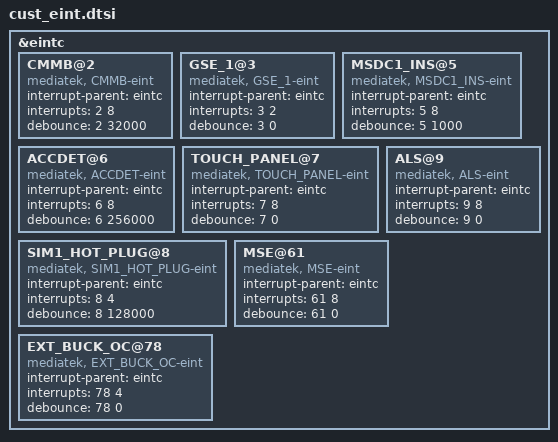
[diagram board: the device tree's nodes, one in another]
/*
 * Generated by MTK SP DrvGen Version 03.13.6 for MT6735M. Copyright MediaTek Inc. (C) 2013.
 * Wed Sep 09 15:29:34 2015
 * Do Not Modify the File.
 */

/*************************
 * EINT DTSI File
*************************/

&eintc {
	CMMB@2 {
		compatible = "mediatek, CMMB-eint";
		interrupt-parent = <&eintc>;
		interrupts = <2 8>;
		debounce = <2 32000>;
	};

	GSE_1@3 {
		compatible = "mediatek, GSE_1-eint";
		interrupt-parent = <&eintc>;
		interrupts = <3 2>;
		debounce = <3 0>;
	};

	MSDC1_INS@5 {
		compatible = "mediatek, MSDC1_INS-eint";
		interrupt-parent = <&eintc>;
		interrupts = <5 8>;
		debounce = <5 1000>;
	};

	ACCDET@6 {
		compatible = "mediatek, ACCDET-eint";
		interrupt-parent = <&eintc>;
		interrupts = <6 8>;
		debounce = <6 256000>;
	};

	TOUCH_PANEL@7 {
		compatible = "mediatek, TOUCH_PANEL-eint";
		interrupt-parent = <&eintc>;
		interrupts = <7 8>;
		debounce = <7 0>;
	};

	SIM1_HOT_PLUG@8 {
		compatible = "mediatek, SIM1_HOT_PLUG-eint";
		interrupt-parent = <&eintc>;
		interrupts = <8 4>;
		debounce = <8 128000>;
	};

	ALS@9 {
		compatible = "mediatek, ALS-eint";
		interrupt-parent = <&eintc>;
		interrupts = <9 8>;
		debounce = <9 0>;
	};

	MSE@61 {
		compatible = "mediatek, MSE-eint";
		interrupt-parent = <&eintc>;
		interrupts = <61 8>;
		debounce = <61 0>;
	};

	EXT_BUCK_OC@78 {
		compatible = "mediatek, EXT_BUCK_OC-eint";
		interrupt-parent = <&eintc>;
		interrupts = <78 4>;
		debounce = <78 0>;
	};

};
